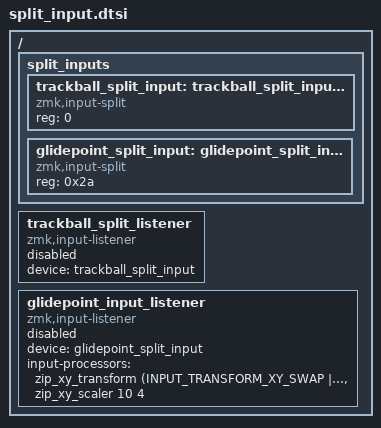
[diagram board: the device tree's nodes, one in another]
/*
    @bravekarma suggests putting *split* input device & input listener nodes here.

    The input listener that is used by the central side is added here but disabled by default.
    This is so that keymaps (which are included for both central and peripheral builds) can reference the listener to add input processors without failing with an undefined reference error.
    About input split device: https://zmk.dev/docs/development/hardware-integration/pointing#shared-configuration-1
*/

/{
    split_inputs { // split input devices
        #address-cells = <1>;
        #size-cells = <0>;

        trackball_split_input: trackball_split_input@0 { // trackball's split input device
            compatible = "zmk,input-split";
            reg = <0>;
        };

        glidepoint_split_input: glidepoint_split_input@2a { // touchpad's split input device
            compatible = "zmk,input-split";
            reg = <0x2a>;
        };
    };

    trackball_split_listener: trackball_split_listener { // listener for split input device
        compatible = "zmk,input-listener";
        status = "disabled"; // disable for .keymap to add input processors without undefined reference error
        device = <&trackball_split_input>;
    };

    glidepoint_input_listener: glidepoint_input_listener {
        compatible = "zmk,input-listener";
        status = "disabled"; // disable for .keymap to add input processors without undefined reference error
        device = <&glidepoint_split_input>;
        // Options for cirque, to be defined in the keyboard shield
        input-processors = <&zip_xy_transform (INPUT_TRANSFORM_XY_SWAP | INPUT_TRANSFORM_X_INVERT | INPUT_TRANSFORM_Y_INVERT) &zip_xy_scaler 10 4>;
    };

};



